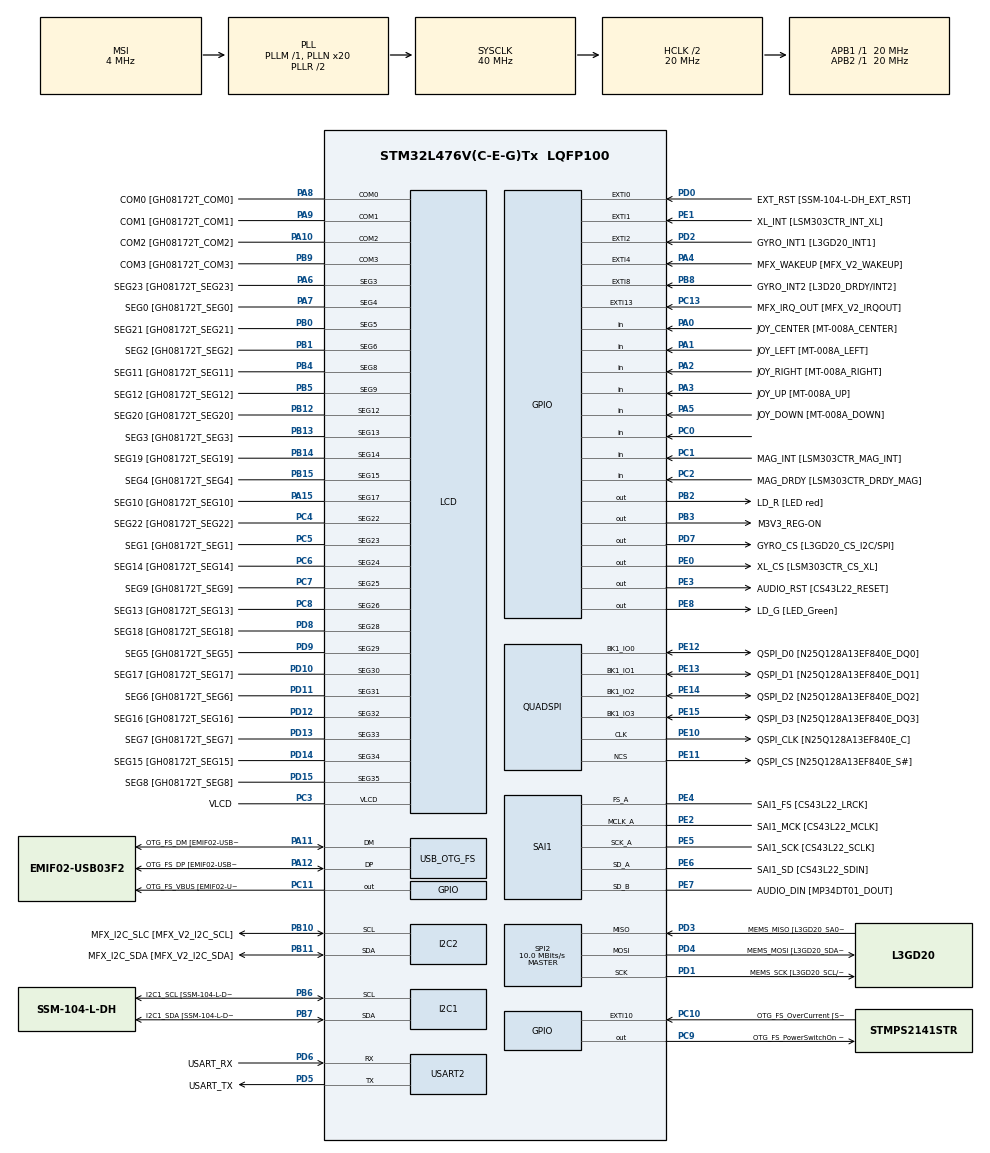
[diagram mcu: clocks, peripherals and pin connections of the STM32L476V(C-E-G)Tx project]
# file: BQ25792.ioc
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I2C1.Timing=0x00404C74
I2C2.Timing=0x00404C74
Mcu.Family=STM32L4
Mcu.Name=STM32L476V(C-E-G)Tx
Mcu.Package=LQFP100
NVIC.OTG_FS_IRQn=true\:0\:0\:false\:false\:true\:true\:true\:true
NVIC.PriorityGroup=NVIC_PRIORITYGROUP_4
NVIC.USART2_IRQn=true\:0\:0\:false\:false\:true\:true\:true\:true
PA0.GPIO_Label=JOY_CENTER [MT-008A_CENTER]
PA0.GPIO_Mode=GPIO_MODE_INPUT
PA0.GPIO_PuPd=GPIO_PULLDOWN
PA0.Signal=GPIO_Input
PA1.GPIO_Label=JOY_LEFT [MT-008A_LEFT]
PA1.GPIO_Mode=GPIO_MODE_INPUT
PA1.GPIO_PuPd=GPIO_PULLDOWN
PA1.Signal=GPIO_Input
PA10.GPIO_Label=COM2 [GH08172T_COM2]
PA10.GPIO_Mode=GPIO_MODE_AF_PP
PA10.GPIO_PuPd=GPIO_NOPULL
PA10.GPIO_Speed=GPIO_SPEED_FREQ_LOW
PA10.Mode=1/4 Duty Cycle
PA10.Signal=LCD_COM2
PA11.GPIO_Label=OTG_FS_DM [EMIF02-USB03F2_D-out]
PA11.GPIO_Mode=GPIO_MODE_AF_PP
PA11.GPIO_PuPd=GPIO_NOPULL
PA11.GPIO_Speed=GPIO_SPEED_FREQ_VERY_HIGH
PA11.Mode=Host_Only
PA11.Signal=USB_OTG_FS_DM
PA12.GPIO_Label=OTG_FS_DP [EMIF02-USB03F2_D+out]
PA12.GPIO_Mode=GPIO_MODE_AF_PP
PA12.GPIO_PuPd=GPIO_NOPULL
PA12.GPIO_Speed=GPIO_SPEED_FREQ_VERY_HIGH
PA12.Mode=Host_Only
PA12.Signal=USB_OTG_FS_DP
PA13\ (JTMS-SWDIO).GPIO_Label=SWDIO
PA13\ (JTMS-SWDIO).Mode=Serial_Wire
PA13\ (JTMS-SWDIO).Signal=SYS_JTMS-SWDIO
PA14\ (JTCK-SWCLK).GPIO_Label=SWCLK
PA14\ (JTCK-SWCLK).Mode=Serial_Wire
PA14\ (JTCK-SWCLK).Signal=SYS_JTCK-SWCLK
PA15\ (JTDI).GPIO_Label=SEG10 [GH08172T_SEG10]
PA15\ (JTDI).GPIO_Mode=GPIO_MODE_AF_PP
PA15\ (JTDI).GPIO_PuPd=GPIO_NOPULL
PA15\ (JTDI).GPIO_Speed=GPIO_SPEED_FREQ_LOW
PA15\ (JTDI).Mode=SEG17
PA15\ (JTDI).Signal=LCD_SEG17
PA2.GPIO_Label=JOY_RIGHT [MT-008A_RIGHT]
PA2.GPIO_Mode=GPIO_MODE_INPUT
PA2.GPIO_PuPd=GPIO_PULLDOWN
PA2.Signal=GPIO_Input
PA3.GPIO_Label=JOY_UP [MT-008A_UP]
PA3.GPIO_Mode=GPIO_MODE_INPUT
PA3.GPIO_PuPd=GPIO_PULLDOWN
PA3.Signal=GPIO_Input
PA4.GPIO_Label=MFX_WAKEUP [MFX_V2_WAKEUP]
PA4.GPIO_ModeDefaultEXTI=GPIO_MODE_EVT_RISING
PA4.GPIO_PuPd=GPIO_NOPULL
PA4.Signal=GPXTI4
PA5.GPIO_Label=JOY_DOWN [MT-008A_DOWN]
PA5.GPIO_Mode=GPIO_MODE_INPUT
PA5.GPIO_PuPd=GPIO_PULLDOWN
PA5.Signal=GPIO_Input
PA6.GPIO_Label=SEG23 [GH08172T_SEG23]
PA6.GPIO_Mode=GPIO_MODE_AF_PP
PA6.GPIO_PuPd=GPIO_NOPULL
PA6.GPIO_Speed=GPIO_SPEED_FREQ_LOW
PA6.Mode=SEG3
PA6.Signal=LCD_SEG3
PA7.GPIO_Label=SEG0 [GH08172T_SEG0]
PA7.GPIO_Mode=GPIO_MODE_AF_PP
PA7.GPIO_PuPd=GPIO_NOPULL
PA7.GPIO_Speed=GPIO_SPEED_FREQ_LOW
PA7.Mode=SEG4
PA7.Signal=LCD_SEG4
PA8.GPIO_Label=COM0 [GH08172T_COM0]
PA8.GPIO_Mode=GPIO_MODE_AF_PP
PA8.GPIO_PuPd=GPIO_NOPULL
PA8.GPIO_Speed=GPIO_SPEED_FREQ_LOW
PA8.Mode=1/4 Duty Cycle
PA8.Signal=LCD_COM0
PA9.GPIO_Label=COM1 [GH08172T_COM1]
PA9.GPIO_Mode=GPIO_MODE_AF_PP
PA9.GPIO_PuPd=GPIO_NOPULL
PA9.GPIO_Speed=GPIO_SPEED_FREQ_LOW
PA9.Mode=1/4 Duty Cycle
PA9.Signal=LCD_COM1
PB0.GPIO_Label=SEG21 [GH08172T_SEG21]
PB0.GPIO_Mode=GPIO_MODE_AF_PP
PB0.GPIO_PuPd=GPIO_NOPULL
PB0.GPIO_Speed=GPIO_SPEED_FREQ_LOW
PB0.Mode=SEG5
PB0.Signal=LCD_SEG5
PB1.GPIO_Label=SEG2 [GH08172T_SEG2]
PB1.GPIO_Mode=GPIO_MODE_AF_PP
PB1.GPIO_PuPd=GPIO_NOPULL
PB1.GPIO_Speed=GPIO_SPEED_FREQ_LOW
PB1.Mode=SEG6
PB1.Signal=LCD_SEG6
PB10.GPIO_Label=MFX_I2C_SLC [MFX_V2_I2C_SCL]
PB10.GPIO_Mode=GPIO_MODE_AF_OD
PB10.GPIO_Pu=GPIO_PULLUP
PB10.GPIO_Speed=GPIO_SPEED_FREQ_VERY_HIGH
PB10.Mode=I2C
PB10.Signal=I2C2_SCL
PB11.GPIO_Label=MFX_I2C_SDA [MFX_V2_I2C_SDA]
PB11.GPIO_Mode=GPIO_MODE_AF_OD
PB11.GPIO_Pu=GPIO_PULLUP
PB11.GPIO_Speed=GPIO_SPEED_FREQ_VERY_HIGH
PB11.Mode=I2C
PB11.Signal=I2C2_SDA
PB12.GPIO_Label=SEG20 [GH08172T_SEG20]
PB12.GPIO_Mode=GPIO_MODE_AF_PP
PB12.GPIO_PuPd=GPIO_NOPULL
PB12.GPIO_Speed=GPIO_SPEED_FREQ_LOW
PB12.Mode=SEG12
PB12.Signal=LCD_SEG12
PB13.GPIO_Label=SEG3 [GH08172T_SEG3]
PB13.GPIO_Mode=GPIO_MODE_AF_PP
PB13.GPIO_PuPd=GPIO_NOPULL
PB13.GPIO_Speed=GPIO_SPEED_FREQ_LOW
PB13.Mode=SEG13
PB13.Signal=LCD_SEG13
PB14.GPIO_Label=SEG19 [GH08172T_SEG19]
PB14.GPIO_Mode=GPIO_MODE_AF_PP
PB14.GPIO_PuPd=GPIO_NOPULL
PB14.GPIO_Speed=GPIO_SPEED_FREQ_LOW
PB14.Mode=SEG14
PB14.Signal=LCD_SEG14
PB15.GPIO_Label=SEG4 [GH08172T_SEG4]
PB15.GPIO_Mode=GPIO_MODE_AF_PP
PB15.GPIO_PuPd=GPIO_NOPULL
PB15.GPIO_Speed=GPIO_SPEED_FREQ_LOW
PB15.Mode=SEG15
PB15.Signal=LCD_SEG15
PB2.GPIO_Label=LD_R [LED red]
PB2.GPIO_ModeDefaultOutputPP=GPIO_MODE_OUTPUT_PP
PB2.GPIO_PuPd=GPIO_PULLUP
PB2.GPIO_Speed=GPIO_SPEED_FREQ_VERY_HIGH
PB2.Signal=GPIO_Output
PB3\ (JTDO-TRACESWO).GPIO_Label=M3V3_REG-ON
PB3\ (JTDO-TRACESWO).GPIO_ModeDefaultOutputPP=GPIO_MODE_OUTPUT_PP
PB3\ (JTDO-TRACESWO).GPIO_PuPd=GPIO_NOPULL
PB3\ (JTDO-TRACESWO).GPIO_Speed=GPIO_SPEED_FREQ_LOW
PB3\ (JTDO-TRACESWO).Signal=GPIO_Output
PB4\ (NJTRST).GPIO_Label=SEG11 [GH08172T_SEG11]
PB4\ (NJTRST).GPIO_Mode=GPIO_MODE_AF_PP
PB4\ (NJTRST).GPIO_PuPd=GPIO_NOPULL
PB4\ (NJTRST).GPIO_Speed=GPIO_SPEED_FREQ_LOW
PB4\ (NJTRST).Mode=SEG8
PB4\ (NJTRST).Signal=LCD_SEG8
PB5.GPIO_Label=SEG12 [GH08172T_SEG12]
PB5.GPIO_Mode=GPIO_MODE_AF_PP
PB5.GPIO_PuPd=GPIO_NOPULL
PB5.GPIO_Speed=GPIO_SPEED_FREQ_LOW
PB5.Mode=SEG9
PB5.Signal=LCD_SEG9
PB6.GPIO_FM6=__NULL
PB6.GPIO_Label=I2C1_SCL [SSM-104-L-DH_SCL]
PB6.GPIO_Mode=GPIO_MODE_AF_OD
PB6.GPIO_Pu=GPIO_PULLUP
PB6.GPIO_Speed=GPIO_SPEED_FREQ_VERY_HIGH
PB6.Mode=I2C
PB6.Signal=I2C1_SCL
PB7.GPIO_FM7=__NULL
PB7.GPIO_Label=I2C1_SDA [SSM-104-L-DH_SDA]
PB7.GPIO_Mode=GPIO_MODE_AF_OD
PB7.GPIO_Pu=GPIO_PULLUP
PB7.GPIO_Speed=GPIO_SPEED_FREQ_VERY_HIGH
PB7.Mode=I2C
PB7.Signal=I2C1_SDA
PB8.GPIO_Label=GYRO_INT2 [L3D20_DRDY/INT2]
PB8.GPIO_ModeDefaultEXTI=GPIO_MODE_EVT_RISING
PB8.GPIO_PuPd=GPIO_NOPULL
PB8.Signal=GPXTI8
PB9.GPIO_FM9=__NULL
PB9.GPIO_Label=COM3 [GH08172T_COM3]
PB9.GPIO_Mode=GPIO_MODE_AF_PP
PB9.GPIO_PuPd=GPIO_NOPULL
PB9.GPIO_Speed=GPIO_SPEED_FREQ_LOW
PB9.Mode=1/4 Duty Cycle
PB9.Signal=LCD_COM3
PC0.Signal=GPIO_Input
PC1.GPIO_Label=MAG_INT [LSM303CTR_MAG_INT]
PC1.GPIO_Mode=GPIO_MODE_INPUT
PC1.GPIO_PuPd=GPIO_NOPULL
PC1.Signal=GPIO_Input
PC10.GPIO_Label=OTG_FS_OverCurrent [STMPS2141STR_FAULT]
PC10.GPIO_ModeDefaultEXTI=GPIO_MODE_EVT_RISING
PC10.GPIO_PuPd=GPIO_NOPULL
PC10.Signal=GPXTI10
PC11.GPIO_Label=OTG_FS_VBUS [EMIF02-USB03F2_Vbus]
PC11.GPIO_ModeDefaultOutputPP=GPIO_MODE_OUTPUT_PP
PC11.GPIO_PuPd=GPIO_NOPULL
PC11.GPIO_Speed=GPIO_SPEED_FREQ_LOW
PC11.Signal=GPIO_Output
PC13.GPIO_Label=MFX_IRQ_OUT [MFX_V2_IRQOUT]
PC13.GPIO_ModeDefaultEXTI=GPIO_MODE_EVT_RISING
PC13.GPIO_PuPd=GPIO_NOPULL
PC13.Signal=GPXTI13
PC14-OSC32_IN\ (PC14).Mode=LSE-External-Oscillator
PC14-OSC32_IN\ (PC14).Signal=RCC_OSC32_IN
PC15-OSC32_OUT\ (PC15).Mode=LSE-External-Oscillator
PC15-OSC32_OUT\ (PC15).Signal=RCC_OSC32_OUT
PC2.GPIO_Label=MAG_DRDY [LSM303CTR_DRDY_MAG]
PC2.GPIO_Mode=GPIO_MODE_INPUT
PC2.GPIO_PuPd=GPIO_NOPULL
PC2.Signal=GPIO_Input
PC3.GPIO_Label=VLCD
PC3.GPIO_Mode=GPIO_MODE_AF_PP
PC3.GPIO_PuPd=GPIO_NOPULL
PC3.GPIO_Speed=GPIO_SPEED_FREQ_LOW
PC3.Mode=1/4 Duty Cycle
PC3.Signal=LCD_VLCD
PC4.GPIO_Label=SEG22 [GH08172T_SEG22]
PC4.GPIO_Mode=GPIO_MODE_AF_PP
PC4.GPIO_PuPd=GPIO_NOPULL
PC4.GPIO_Speed=GPIO_SPEED_FREQ_LOW
PC4.Mode=SEG22
PC4.Signal=LCD_SEG22
PC5.GPIO_Label=SEG1 [GH08172T_SEG1]
PC5.GPIO_Mode=GPIO_MODE_AF_PP
PC5.GPIO_PuPd=GPIO_NOPULL
PC5.GPIO_Speed=GPIO_SPEED_FREQ_LOW
PC5.Mode=SEG23
PC5.Signal=LCD_SEG23
PC6.GPIO_Label=SEG14 [GH08172T_SEG14]
PC6.GPIO_Mode=GPIO_MODE_AF_PP
PC6.GPIO_PuPd=GPIO_NOPULL
PC6.GPIO_Speed=GPIO_SPEED_FREQ_LOW
PC6.Mode=SEG24
PC6.Signal=LCD_SEG24
PC7.GPIO_Label=SEG9 [GH08172T_SEG9]
PC7.GPIO_Mode=GPIO_MODE_AF_PP
PC7.GPIO_PuPd=GPIO_NOPULL
PC7.GPIO_Speed=GPIO_SPEED_FREQ_LOW
PC7.Mode=SEG25
PC7.Signal=LCD_SEG25
PC8.GPIO_Label=SEG13 [GH08172T_SEG13]
PC8.GPIO_Mode=GPIO_MODE_AF_PP
PC8.GPIO_PuPd=GPIO_NOPULL
PC8.GPIO_Speed=GPIO_SPEED_FREQ_LOW
PC8.Mode=SEG26
PC8.Signal=LCD_SEG26
PC9.GPIO_Label=OTG_FS_PowerSwitchOn [STMPS2141STR_EN]
PC9.GPIO_ModeDefaultOutputPP=GPIO_MODE_OUTPUT_PP
PC9.GPIO_PuPd=GPIO_NOPULL
PC9.GPIO_Speed=GPIO_SPEED_FREQ_LOW
PC9.PinState=GPIO_PIN_SET
PC9.Signal=GPIO_Output
PD0.GPIO_Label=EXT_RST [SSM-104-L-DH_EXT_RST]
PD0.GPIO_ModeDefaultEXTI=GPIO_MODE_EVT_RISING
PD0.GPIO_PuPd=GPIO_NOPULL
PD0.Signal=GPXTI0
PD1.GPIO_Label=MEMS_SCK [L3GD20_SCL/SPC]
PD1.GPIO_Mode=GPIO_MODE_AF_PP
PD1.GPIO_PuPd=GPIO_NOPULL
PD1.GPIO_Speed=GPIO_SPEED_FREQ_VERY_HIGH
PD1.Mode=Full_Duplex_Master
PD1.Signal=SPI2_SCK
PD10.GPIO_Label=SEG17 [GH08172T_SEG17]
PD10.GPIO_Mode=GPIO_MODE_AF_PP
PD10.GPIO_PuPd=GPIO_NOPULL
PD10.GPIO_Speed=GPIO_SPEED_FREQ_LOW
PD10.Mode=SEG30
PD10.Signal=LCD_SEG30
PD11.GPIO_Label=SEG6 [GH08172T_SEG6]
PD11.GPIO_Mode=GPIO_MODE_AF_PP
PD11.GPIO_PuPd=GPIO_NOPULL
PD11.GPIO_Speed=GPIO_SPEED_FREQ_LOW
PD11.Mode=SEG31
PD11.Signal=LCD_SEG31
PD12.GPIO_Label=SEG16 [GH08172T_SEG16]
PD12.GPIO_Mode=GPIO_MODE_AF_PP
PD12.GPIO_PuPd=GPIO_NOPULL
PD12.GPIO_Speed=GPIO_SPEED_FREQ_LOW
PD12.Mode=SEG32
PD12.Signal=LCD_SEG32
PD13.GPIO_Label=SEG7 [GH08172T_SEG7]
PD13.GPIO_Mode=GPIO_MODE_AF_PP
PD13.GPIO_PuPd=GPIO_NOPULL
PD13.GPIO_Speed=GPIO_SPEED_FREQ_LOW
PD13.Mode=SEG33
PD13.Signal=LCD_SEG33
PD14.GPIO_Label=SEG15 [GH08172T_SEG15]
PD14.GPIO_Mode=GPIO_MODE_AF_PP
PD14.GPIO_PuPd=GPIO_NOPULL
PD14.GPIO_Speed=GPIO_SPEED_FREQ_LOW
PD14.Mode=SEG34
PD14.Signal=LCD_SEG34
PD15.GPIO_Label=SEG8 [GH08172T_SEG8]
PD15.GPIO_Mode=GPIO_MODE_AF_PP
PD15.GPIO_PuPd=GPIO_NOPULL
PD15.GPIO_Speed=GPIO_SPEED_FREQ_LOW
PD15.Mode=SEG35
PD15.Signal=LCD_SEG35
PD2.GPIO_Label=GYRO_INT1 [L3GD20_INT1]
PD2.GPIO_ModeDefaultEXTI=GPIO_MODE_EVT_RISING
PD2.GPIO_PuPd=GPIO_NOPULL
PD2.Signal=GPXTI2
PD3.GPIO_Label=MEMS_MISO [L3GD20_SA0/SDO]
PD3.GPIO_Mode=GPIO_MODE_AF_PP
PD3.GPIO_PuPd=GPIO_NOPULL
PD3.GPIO_Speed=GPIO_SPEED_FREQ_VERY_HIGH
PD3.Mode=Full_Duplex_Master
PD3.Signal=SPI2_MISO
PD4.GPIO_Label=MEMS_MOSI [L3GD20_SDA/SDI/SDO]
PD4.GPIO_Mode=GPIO_MODE_AF_PP
PD4.GPIO_PuPd=GPIO_NOPULL
PD4.GPIO_Speed=GPIO_SPEED_FREQ_VERY_HIGH
PD4.Mode=Full_Duplex_Master
PD4.Signal=SPI2_MOSI
PD5.GPIO_Label=USART_TX
PD5.GPIO_Mode=GPIO_MODE_AF_PP
PD5.GPIO_PuPd=GPIO_PULLUP
PD5.GPIO_Speed=GPIO_SPEED_FREQ_VERY_HIGH
PD5.Mode=Asynchronous
PD5.Signal=USART2_TX
PD6.GPIO_Label=USART_RX
PD6.GPIO_Mode=GPIO_MODE_AF_PP
PD6.GPIO_PuPd=GPIO_PULLUP
PD6.GPIO_Speed=GPIO_SPEED_FREQ_VERY_HIGH
PD6.Mode=Asynchronous
PD6.Signal=USART2_RX
PD7.GPIO_Label=GYRO_CS [L3GD20_CS_I2C/SPI]
PD7.GPIO_ModeDefaultOutputPP=GPIO_MODE_OUTPUT_PP
PD7.GPIO_PuPd=GPIO_NOPULL
PD7.GPIO_Speed=GPIO_SPEED_FREQ_VERY_HIGH
PD7.Signal=GPIO_Output
PD8.GPIO_Label=SEG18 [GH08172T_SEG18]
PD8.GPIO_Mode=GPIO_MODE_AF_PP
PD8.GPIO_PuPd=GPIO_NOPULL
PD8.GPIO_Speed=GPIO_SPEED_FREQ_LOW
PD8.Mode=SEG28
PD8.Signal=LCD_SEG28
PD9.GPIO_Label=SEG5 [GH08172T_SEG5]
PD9.GPIO_Mode=GPIO_MODE_AF_PP
PD9.GPIO_PuPd=GPIO_NOPULL
PD9.GPIO_Speed=GPIO_SPEED_FREQ_LOW
PD9.Mode=SEG29
PD9.Signal=LCD_SEG29
PE0.GPIO_Label=XL_CS [LSM303CTR_CS_XL]
PE0.GPIO_ModeDefaultOutputPP=GPIO_MODE_OUTPUT_PP
PE0.GPIO_PuPd=GPIO_NOPULL
PE0.GPIO_Speed=GPIO_SPEED_FREQ_LOW
PE0.Signal=GPIO_Output
PE1.GPIO_Label=XL_INT [LSM303CTR_INT_XL]
PE1.GPIO_ModeDefaultEXTI=GPIO_MODE_EVT_RISING
PE1.GPIO_PuPd=GPIO_NOPULL
PE1.Signal=GPXTI1
PE10.GPIO_Label=QSPI_CLK [N25Q128A13EF840E_C]
PE10.GPIO_Mode=GPIO_MODE_AF_PP
PE10.GPIO_PuPd=GPIO_NOPULL
PE10.GPIO_Speed=GPIO_SPEED_FREQ_VERY_HIGH
PE10.Mode=Single Bank
PE10.Signal=QUADSPI_CLK
PE11.GPIO_Label=QSPI_CS [N25Q128A13EF840E_S\#]
PE11.GPIO_Mode=GPIO_MODE_AF_PP
PE11.GPIO_PuPd=GPIO_NOPULL
PE11.GPIO_Speed=GPIO_SPEED_FREQ_VERY_HIGH
PE11.Mode=Single Bank
PE11.Signal=QUADSPI_NCS
PE12.GPIO_Label=QSPI_D0 [N25Q128A13EF840E_DQ0]
PE12.GPIO_Mode=GPIO_MODE_AF_PP
PE12.GPIO_PuPd=GPIO_NOPULL
PE12.GPIO_Speed=GPIO_SPEED_FREQ_VERY_HIGH
PE12.Mode=Single Bank
PE12.Signal=QUADSPI_BK1_IO0
PE13.GPIO_Label=QSPI_D1 [N25Q128A13EF840E_DQ1]
PE13.GPIO_Mode=GPIO_MODE_AF_PP
PE13.GPIO_PuPd=GPIO_NOPULL
PE13.GPIO_Speed=GPIO_SPEED_FREQ_VERY_HIGH
PE13.Mode=Single Bank
PE13.Signal=QUADSPI_BK1_IO1
PE14.GPIO_Label=QSPI_D2 [N25Q128A13EF840E_DQ2]
PE14.GPIO_Mode=GPIO_MODE_AF_PP
PE14.GPIO_PuPd=GPIO_NOPULL
PE14.GPIO_Speed=GPIO_SPEED_FREQ_VERY_HIGH
PE14.Mode=Single Bank
PE14.Signal=QUADSPI_BK1_IO2
PE15.GPIO_Label=QSPI_D3 [N25Q128A13EF840E_DQ3]
PE15.GPIO_Mode=GPIO_MODE_AF_PP
PE15.GPIO_PuPd=GPIO_NOPULL
PE15.GPIO_Speed=GPIO_SPEED_FREQ_VERY_HIGH
PE15.Mode=Single Bank
PE15.Signal=QUADSPI_BK1_IO3
PE2.GPIO_Label=SAI1_MCK [CS43L22_MCLK]
PE2.GPIO_Mode=GPIO_MODE_AF_PP
PE2.GPIO_PuPd=GPIO_NOPULL
PE2.GPIO_Speed=GPIO_SPEED_FREQ_VERY_HIGH
PE2.Mode=SAI_A_MasterWithClock
PE2.Signal=SAI1_MCLK_A
PE3.GPIO_Label=AUDIO_RST [CS43L22_RESET]
PE3.GPIO_ModeDefaultOutputPP=GPIO_MODE_OUTPUT_PP
PE3.GPIO_PuPd=GPIO_NOPULL
PE3.GPIO_Speed=GPIO_SPEED_FREQ_HIGH
PE3.Signal=GPIO_Output
PE4.GPIO_Label=SAI1_FS [CS43L22_LRCK]
PE4.GPIO_Mode=GPIO_MODE_AF_PP
PE4.GPIO_PuPd=GPIO_NOPULL
PE4.GPIO_Speed=GPIO_SPEED_FREQ_VERY_HIGH
PE4.Mode=SAI_A_MasterWithClock
PE4.Signal=SAI1_FS_A
PE5.GPIO_Label=SAI1_SCK [CS43L22_SCLK]
PE5.GPIO_Mode=GPIO_MODE_AF_PP
PE5.GPIO_PuPd=GPIO_NOPULL
PE5.GPIO_Speed=GPIO_SPEED_FREQ_VERY_HIGH
PE5.Mode=SAI_A_MasterWithClock
PE5.Signal=SAI1_SCK_A
PE6.GPIO_Label=SAI1_SD [CS43L22_SDIN]
PE6.GPIO_Mode=GPIO_MODE_AF_PP
PE6.GPIO_PuPd=GPIO_NOPULL
PE6.GPIO_Speed=GPIO_SPEED_FREQ_VERY_HIGH
PE6.Mode=SAI_A_MasterWithClock
PE6.Signal=SAI1_SD_A
PE7.GPIO_Label=AUDIO_DIN [MP34DT01_DOUT]
PE7.GPIO_Mode=GPIO_MODE_AF_PP
PE7.GPIO_PuPd=GPIO_NOPULL
PE7.GPIO_Speed=GPIO_SPEED_FREQ_VERY_HIGH
PE7.Mode=SAI_B_SyncSlave
PE7.Signal=SAI1_SD_B
PE8.GPIO_Label=LD_G [LED_Green]
PE8.GPIO_ModeDefaultOutputPP=GPIO_MODE_OUTPUT_PP
PE8.GPIO_PuPd=GPIO_PULLUP
PE8.GPIO_Speed=GPIO_SPEED_FREQ_VERY_HIGH
PE8.Signal=GPIO_Output
PE9.GPIO_Label=AUDIO_CLK [MP34DT01_CLK]
PE9.GPIO_Mode=GPIO_MODE_AF_PP
PE9.GPIO_PuPd=GPIO_NOPULL
PE9.GPIO_Speed=GPIO_SPEED_FREQ_LOW
PE9.Signal=SAI1_FS_B
PH0-OSC_IN\ (PH0).Mode=HSE-External-Oscillator
PH0-OSC_IN\ (PH0).Signal=RCC_OSC_IN
PH1-OSC_OUT\ (PH1).Mode=HSE-External-Oscillator
PH1-OSC_OUT\ (PH1).Signal=RCC_OSC_OUT
ProjectManager.HeapSize=0x200
ProjectManager.StackSize=0x400
ProjectManager.TargetToolchain=STM32CubeIDE
QUADSPI.ClockPrescaler=1
QUADSPI.FifoThreshold=4
QUADSPI.FlashSize=24
QUADSPI.SampleShifting=QSPI_SAMPLE_SHIFTING_HALFCYCLE
RCC.ADCFreq_Value=48000000
RCC.AHBCLKDivider=RCC_SYSCLK_DIV2
RCC.AHBFreq_Value=20000000
RCC.APB1Freq_Value=20000000
RCC.APB1TimFreq_Value=20000000
RCC.APB2Freq_Value=20000000
RCC.APB2TimFreq_Value=20000000
RCC.CortexFreq_Value=20000000
RCC.HCLKFreq_Value=20000000
RCC.HSE_VALUE=8000000
RCC.HSI_VALUE=16000000
RCC.MSI_VALUE=4000000
RCC.PLLN=20
RCC.PLLSAI1N=24
RCC.PREFETCH_ENABLE=1
RCC.SYSCLKFreq_VALUE=40000000
RCC.SYSCLKSource=RCC_SYSCLKSOURCE_PLLCLK
RCC.USBFreq_Value=48000000
RCC.VCOOutputFreq_Value=80000000
SAI1.Instance-SAI_A_MasterWithClock=SAI$Index_Block_A
SAI1.Instance-SAI_B_SyncSlave=SAI$Index_Block_B
SAI1.MClockEnable-SAI_A_MasterWithClock=SAI_MASTERCLOCK_ENABLE
SAI1.Synchro-SAI_B_SyncSlave=SAI_SYNCHRONOUS
SAI1.VirtualMode-SAI_A_MasterWithClock=VM_MASTER
SAI1.VirtualMode-SAI_B_SyncSlave=VM_SLAVE
SPI2.CalculateBaudRate=10.0 MBits/s
SPI2.Direction=SPI_DIRECTION_2LINES
SPI2.Mode=SPI_MODE_MASTER
SPI2.VirtualType=VM_MASTER
USART2.VirtualMode-Asynchronous=VM_ASYNC
USB_HOST.BSP.number=1
USB_HOST.USBH_HandleTypeDef=hUsbHostFS
USB_HOST.VirtualModeFS=Cdc
USB_HOST0.BSP.STBoard=false
USB_HOST0.BSP.api=Unknown
USB_HOST0.BSP.instance=PC9
USB_HOST0.BSP.ip=GPIO
USB_HOST0.BSP.mode=Output
USB_HOST0.BSP.name=Drive_VBUS_FS
USB_HOST0.BSP.solution=PC9
USB_OTG_FS.VirtualMode=Host_Only
USB_OTG_FS.phy_itface=HCD_PHY_EMBEDDED
VP_USB_HOST_VS_USB_HOST_CDC_FS.Mode=CDC_FS
board=STM32L476G-DISCO

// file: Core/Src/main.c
/* USER CODE BEGIN Header */
/**
  ******************************************************************************
  * @file           : main.c
  * @brief          : Main program body
  ******************************************************************************
  * @attention
  *
  * Copyright (c) 2023 STMicroelectronics.
  * All rights reserved.
  *
  * This software is licensed under terms that can be found in the LICENSE file
  * in the root directory of this software component.
  * If no LICENSE file comes with this software, it is provided AS-IS.
  *
  ******************************************************************************
  */
/* USER CODE END Header */
#include "main.h"
#include "usb_host.h"

/* USER CODE BEGIN Includes */
#include "stdlib.h"
#include "BQ25792.h"
#include "ncurses.h"
/* USER CODE END Includes */

/* USER CODE BEGIN PD */

#define I2C_EEPROM_ADDRESS 0xA0
#define I2C_BQ25792_ADDRESS (0x6B<<1)
/* USER CODE END PD */

I2C_HandleTypeDef hi2c1;
I2C_HandleTypeDef hi2c2;

LCD_HandleTypeDef hlcd;

QSPI_HandleTypeDef hqspi;

SAI_HandleTypeDef hsai_BlockA1;
SAI_HandleTypeDef hsai_BlockB1;

SPI_HandleTypeDef hspi2;

UART_HandleTypeDef huart2;

void SystemClock_Config(void);
void PeriphCommonClock_Config(void);
static void MX_GPIO_Init(void);
static void MX_I2C1_Init(void);
static void MX_I2C2_Init(void);
static void MX_LCD_Init(void);
static void MX_QUADSPI_Init(void);
static void MX_SAI1_Init(void);
static void MX_SPI2_Init(void);
static void MX_USART2_UART_Init(void);
void MX_USB_HOST_Process(void);

int main(void)
{
  /* USER CODE BEGIN 1 */

	char bufforTx[128];
	int len;
  /* USER CODE END 1 */

  /* MCU Configuration--------------------------------------------------------*/

  /* Reset of all peripherals, Initializes the Flash interface and the Systick. */
  HAL_Init();

  /* Configure the system clock */
  SystemClock_Config();

/* Configure the peripherals common clocks */
  PeriphCommonClock_Config();

  /* Initialize all configured peripherals */
  MX_GPIO_Init();
  MX_I2C1_Init();
  MX_I2C2_Init();
  MX_LCD_Init();
  MX_QUADSPI_Init();
  MX_SAI1_Init();
  MX_SPI2_Init();
  MX_USART2_UART_Init();
  MX_USB_HOST_Init();
  /* USER CODE BEGIN 2 */

  //when compiled
	HAL_UART_Transmit(&huart2, "\f", 1, 10);
	len = sprintf(bufforTx,"%sCompiled @ %s %s\r\n", NCURSES_RESET, __DATE__, __TIME__);
	HAL_UART_Transmit(&huart2, bufforTx, len, 10);

  if(BQ25792_Init() != HAL_OK)
  {
  	  HAL_UART_Transmit(&huart2, "BQ25792_Init: Hal error\r\n", 25, 10);
  	  while(1);
  }
  /* USER CODE END 2 */

  /* Infinite loop */
  while (1)
  {
    MX_USB_HOST_Process();

    /* USER CODE BEGIN 3 */

    BQ25792_Debug();

    HAL_Delay(500);
    HAL_GPIO_TogglePin(LD_G_GPIO_Port, LD_G_Pin);

    if(HAL_GPIO_ReadPin(JOY_CENTER_GPIO_Port, JOY_CENTER_Pin))
    {
		char pData[1];
		if(BQ25792_Read(BQ25792_CHARGER_CONTROL_0, pData, 1) == HAL_OK)
		{
			pData[0] ^= BQ25792_CHARGER_CONTROL_0_EN_CHG;
			BQ25792_Write(BQ25792_CHARGER_CONTROL_0, pData, 1);
		}
    }

    if(HAL_GPIO_ReadPin(JOY_UP_GPIO_Port, JOY_UP_Pin))
	{
		char pData[2];
		if(BQ25792_Read(BQ25792_CHARGE_CURRENT_LIMIT, pData, 2) == HAL_OK)
		{
			int current = pData[0] << 8 | pData[1];
			if(current < 500)
				current++;
			if(current > 500)
				current = 500;
			pData[0] = (current << 8) & 0xff;
			pData[1] = current & 0xff;
			BQ25792_Write(BQ25792_CHARGE_CURRENT_LIMIT, pData, 2);
		}
	}
    else if(HAL_GPIO_ReadPin(JOY_DOWN_GPIO_Port, JOY_DOWN_Pin))
	{
		char pData[2];
		if(BQ25792_Read(BQ25792_CHARGE_CURRENT_LIMIT, pData, 2) == HAL_OK)
		{
			int current = pData[0] << 8 | pData[1];
			if(current > 5)
				current--;
			if(current < 5)
				current = 5;
			pData[0] = (current << 8) & 0xff;
			pData[1] = current & 0xff;
			BQ25792_Write(BQ25792_CHARGE_CURRENT_LIMIT, pData, 2);
		}
	}

    if(HAL_GPIO_ReadPin(JOY_LEFT_GPIO_Port, JOY_LEFT_Pin))
    {
		char pData[1];
		if(BQ25792_Read(BQ25792_CHARGER_CONTROL_3, pData, 1) == HAL_OK)
		{
			pData[0] ^= BQ25792_CHARGER_CONTROL_3_EN_OTG;
			BQ25792_Write(BQ25792_CHARGER_CONTROL_3, pData, 1);
		}
    }

    if(BQ25792_WD_Feed() != HAL_OK)
    {
    	while(1)
        {
    		HAL_Delay(100);
            HAL_GPIO_TogglePin(LD_R_GPIO_Port, LD_R_Pin);
        }
    }
  }
  /* USER CODE END 3 */
}

void SystemClock_Config(void)
{
  RCC_OscInitTypeDef RCC_OscInitStruct = {0};
  RCC_ClkInitTypeDef RCC_ClkInitStruct = {0};

  /** Configure the main internal regulator output voltage
  */
  if (HAL_PWREx_ControlVoltageScaling(PWR_REGULATOR_VOLTAGE_SCALE1) != HAL_OK)
  {
    Error_Handler();
  }

  /** Configure LSE Drive Capability
  */
  HAL_PWR_EnableBkUpAccess();
  __HAL_RCC_LSEDRIVE_CONFIG(RCC_LSEDRIVE_LOW);

  /** Initializes the RCC Oscillators according to the specified parameters
  * in the RCC_OscInitTypeDef structure.
  */
  RCC_OscInitStruct.OscillatorType = RCC_OSCILLATORTYPE_LSI|RCC_OSCILLATORTYPE_LSE
                              |RCC_OSCILLATORTYPE_MSI;
  RCC_OscInitStruct.LSEState = RCC_LSE_ON;
  RCC_OscInitStruct.LSIState = RCC_LSI_ON;
  RCC_OscInitStruct.MSIState = RCC_MSI_ON;
  RCC_OscInitStruct.MSICalibrationValue = 0;
  RCC_OscInitStruct.MSIClockRange = RCC_MSIRANGE_6;
  RCC_OscInitStruct.PLL.PLLState = RCC_PLL_ON;
  RCC_OscInitStruct.PLL.PLLSource = RCC_PLLSOURCE_MSI;
  RCC_OscInitStruct.PLL.PLLM = 1;
  RCC_OscInitStruct.PLL.PLLN = 20;
  RCC_OscInitStruct.PLL.PLLP = RCC_PLLP_DIV7;
  RCC_OscInitStruct.PLL.PLLQ = RCC_PLLQ_DIV2;
  RCC_OscInitStruct.PLL.PLLR = RCC_PLLR_DIV2;
  if (HAL_RCC_OscConfig(&RCC_OscInitStruct) != HAL_OK)
  {
    Error_Handler();
  }

  /** Initializes the CPU, AHB and APB buses clocks
  */
  RCC_ClkInitStruct.ClockType = RCC_CLOCKTYPE_HCLK|RCC_CLOCKTYPE_SYSCLK
                              |RCC_CLOCKTYPE_PCLK1|RCC_CLOCKTYPE_PCLK2;
  RCC_ClkInitStruct.SYSCLKSource = RCC_SYSCLKSOURCE_PLLCLK;
  RCC_ClkInitStruct.AHBCLKDivider = RCC_SYSCLK_DIV2;
  RCC_ClkInitStruct.APB1CLKDivider = RCC_HCLK_DIV1;
  RCC_ClkInitStruct.APB2CLKDivider = RCC_HCLK_DIV1;

  if (HAL_RCC_ClockConfig(&RCC_ClkInitStruct, FLASH_LATENCY_1) != HAL_OK)
  {
    Error_Handler();
  }

  /** Enable MSI Auto calibration
  */
  HAL_RCCEx_EnableMSIPLLMode();
}

void PeriphCommonClock_Config(void)
{
  RCC_PeriphCLKInitTypeDef PeriphClkInit = {0};

  /** Initializes the peripherals clock
  */
  PeriphClkInit.PeriphClockSelection = RCC_PERIPHCLK_SAI1|RCC_PERIPHCLK_USB;
  PeriphClkInit.Sai1ClockSelection = RCC_SAI1CLKSOURCE_PLLSAI1;
  PeriphClkInit.UsbClockSelection = RCC_USBCLKSOURCE_PLLSAI1;
  PeriphClkInit.PLLSAI1.PLLSAI1Source = RCC_PLLSOURCE_MSI;
  PeriphClkInit.PLLSAI1.PLLSAI1M = 1;
  PeriphClkInit.PLLSAI1.PLLSAI1N = 24;
  PeriphClkInit.PLLSAI1.PLLSAI1P = RCC_PLLP_DIV7;
  PeriphClkInit.PLLSAI1.PLLSAI1Q = RCC_PLLQ_DIV2;
  PeriphClkInit.PLLSAI1.PLLSAI1R = RCC_PLLR_DIV2;
  PeriphClkInit.PLLSAI1.PLLSAI1ClockOut = RCC_PLLSAI1_SAI1CLK|RCC_PLLSAI1_48M2CLK;
  if (HAL_RCCEx_PeriphCLKConfig(&PeriphClkInit) != HAL_OK)
  {
    Error_Handler();
  }
}

static void MX_I2C1_Init(void)
{

  hi2c1.Instance = I2C1;
  hi2c1.Init.Timing = 0x00404C74;
  hi2c1.Init.OwnAddress1 = 0;
  hi2c1.Init.AddressingMode = I2C_ADDRESSINGMODE_7BIT;
  hi2c1.Init.DualAddressMode = I2C_DUALADDRESS_DISABLE;
  hi2c1.Init.OwnAddress2 = 0;
  hi2c1.Init.OwnAddress2Masks = I2C_OA2_NOMASK;
  hi2c1.Init.GeneralCallMode = I2C_GENERALCALL_DISABLE;
  hi2c1.Init.NoStretchMode = I2C_NOSTRETCH_DISABLE;
  if (HAL_I2C_Init(&hi2c1) != HAL_OK)
  {
    Error_Handler();
  }

  /** Configure Analogue filter
  */
  if (HAL_I2CEx_ConfigAnalogFilter(&hi2c1, I2C_ANALOGFILTER_ENABLE) != HAL_OK)
  {
    Error_Handler();
  }

  /** Configure Digital filter
  */
  if (HAL_I2CEx_ConfigDigitalFilter(&hi2c1, 0) != HAL_OK)
  {
    Error_Handler();
  }

}

static void MX_I2C2_Init(void)
{

  hi2c2.Instance = I2C2;
  hi2c2.Init.Timing = 0x00404C74;
  hi2c2.Init.OwnAddress1 = 0;
  hi2c2.Init.AddressingMode = I2C_ADDRESSINGMODE_7BIT;
  hi2c2.Init.DualAddressMode = I2C_DUALADDRESS_DISABLE;
  hi2c2.Init.OwnAddress2 = 0;
  hi2c2.Init.OwnAddress2Masks = I2C_OA2_NOMASK;
  hi2c2.Init.GeneralCallMode = I2C_GENERALCALL_DISABLE;
  hi2c2.Init.NoStretchMode = I2C_NOSTRETCH_DISABLE;
  if (HAL_I2C_Init(&hi2c2) != HAL_OK)
  {
    Error_Handler();
  }

  /** Configure Analogue filter
  */
  if (HAL_I2CEx_ConfigAnalogFilter(&hi2c2, I2C_ANALOGFILTER_ENABLE) != HAL_OK)
  {
    Error_Handler();
  }

  /** Configure Digital filter
  */
  if (HAL_I2CEx_ConfigDigitalFilter(&hi2c2, 0) != HAL_OK)
  {
    Error_Handler();
  }

}

static void MX_LCD_Init(void)
{

  hlcd.Instance = LCD;
  hlcd.Init.Prescaler = LCD_PRESCALER_1;
  hlcd.Init.Divider = LCD_DIVIDER_16;
  hlcd.Init.Duty = LCD_DUTY_1_4;
  hlcd.Init.Bias = LCD_BIAS_1_4;
  hlcd.Init.VoltageSource = LCD_VOLTAGESOURCE_INTERNAL;
  hlcd.Init.Contrast = LCD_CONTRASTLEVEL_0;
  hlcd.Init.DeadTime = LCD_DEADTIME_0;
  hlcd.Init.PulseOnDuration = LCD_PULSEONDURATION_0;
  hlcd.Init.MuxSegment = LCD_MUXSEGMENT_DISABLE;
  hlcd.Init.BlinkMode = LCD_BLINKMODE_OFF;
  hlcd.Init.BlinkFrequency = LCD_BLINKFREQUENCY_DIV8;
  hlcd.Init.HighDrive = LCD_HIGHDRIVE_DISABLE;
  if (HAL_LCD_Init(&hlcd) != HAL_OK)
  {
    Error_Handler();
  }

}

static void MX_QUADSPI_Init(void)
{

  /* QUADSPI parameter configuration*/
  hqspi.Instance = QUADSPI;
  hqspi.Init.ClockPrescaler = 1;
  hqspi.Init.FifoThreshold = 4;
  hqspi.Init.SampleShifting = QSPI_SAMPLE_SHIFTING_HALFCYCLE;
  hqspi.Init.FlashSize = 24;
  hqspi.Init.ChipSelectHighTime = QSPI_CS_HIGH_TIME_1_CYCLE;
  hqspi.Init.ClockMode = QSPI_CLOCK_MODE_0;
  if (HAL_QSPI_Init(&hqspi) != HAL_OK)
  {
    Error_Handler();
  }

}

static void MX_SAI1_Init(void)
{

  hsai_BlockA1.Instance = SAI1_Block_A;
  hsai_BlockA1.Init.Protocol = SAI_FREE_PROTOCOL;
  hsai_BlockA1.Init.AudioMode = SAI_MODEMASTER_TX;
  hsai_BlockA1.Init.DataSize = SAI_DATASIZE_8;
  hsai_BlockA1.Init.FirstBit = SAI_FIRSTBIT_MSB;
  hsai_BlockA1.Init.ClockStrobing = SAI_CLOCKSTROBING_FALLINGEDGE;
  hsai_BlockA1.Init.Synchro = SAI_ASYNCHRONOUS;
  hsai_BlockA1.Init.OutputDrive = SAI_OUTPUTDRIVE_DISABLE;
  hsai_BlockA1.Init.NoDivider = SAI_MASTERDIVIDER_ENABLE;
  hsai_BlockA1.Init.FIFOThreshold = SAI_FIFOTHRESHOLD_EMPTY;
  hsai_BlockA1.Init.AudioFrequency = SAI_AUDIO_FREQUENCY_192K;
  hsai_BlockA1.Init.SynchroExt = SAI_SYNCEXT_DISABLE;
  hsai_BlockA1.Init.MonoStereoMode = SAI_STEREOMODE;
  hsai_BlockA1.Init.CompandingMode = SAI_NOCOMPANDING;
  hsai_BlockA1.Init.TriState = SAI_OUTPUT_NOTRELEASED;
  hsai_BlockA1.FrameInit.FrameLength = 8;
  hsai_BlockA1.FrameInit.ActiveFrameLength = 1;
  hsai_BlockA1.FrameInit.FSDefinition = SAI_FS_STARTFRAME;
  hsai_BlockA1.FrameInit.FSPolarity = SAI_FS_ACTIVE_LOW;
  hsai_BlockA1.FrameInit.FSOffset = SAI_FS_FIRSTBIT;
  hsai_BlockA1.SlotInit.FirstBitOffset = 0;
  hsai_BlockA1.SlotInit.SlotSize = SAI_SLOTSIZE_DATASIZE;
  hsai_BlockA1.SlotInit.SlotNumber = 1;
  hsai_BlockA1.SlotInit.SlotActive = 0x00000000;
  if (HAL_SAI_Init(&hsai_BlockA1) != HAL_OK)
  {
    Error_Handler();
  }
  hsai_BlockB1.Instance = SAI1_Block_B;
  hsai_BlockB1.Init.Protocol = SAI_FREE_PROTOCOL;
  hsai_BlockB1.Init.AudioMode = SAI_MODESLAVE_RX;
  hsai_BlockB1.Init.DataSize = SAI_DATASIZE_8;
  hsai_BlockB1.Init.FirstBit = SAI_FIRSTBIT_MSB;
  hsai_BlockB1.Init.ClockStrobing = SAI_CLOCKSTROBING_FALLINGEDGE;
  hsai_BlockB1.Init.Synchro = SAI_SYNCHRONOUS;
  hsai_BlockB1.Init.OutputDrive = SAI_OUTPUTDRIVE_DISABLE;
  hsai_BlockB1.Init.FIFOThreshold = SAI_FIFOTHRESHOLD_EMPTY;
  hsai_BlockB1.Init.SynchroExt = SAI_SYNCEXT_DISABLE;
  hsai_BlockB1.Init.MonoStereoMode = SAI_STEREOMODE;
  hsai_BlockB1.Init.CompandingMode = SAI_NOCOMPANDING;
  hsai_BlockB1.Init.TriState = SAI_OUTPUT_NOTRELEASED;
  hsai_BlockB1.FrameInit.FrameLength = 8;
  hsai_BlockB1.FrameInit.ActiveFrameLength = 1;
  hsai_BlockB1.FrameInit.FSDefinition = SAI_FS_STARTFRAME;
  hsai_BlockB1.FrameInit.FSPolarity = SAI_FS_ACTIVE_LOW;
  hsai_BlockB1.FrameInit.FSOffset = SAI_FS_FIRSTBIT;
  hsai_BlockB1.SlotInit.FirstBitOffset = 0;
  hsai_BlockB1.SlotInit.SlotSize = SAI_SLOTSIZE_DATASIZE;
  hsai_BlockB1.SlotInit.SlotNumber = 1;
  hsai_BlockB1.SlotInit.SlotActive = 0x00000000;
  if (HAL_SAI_Init(&hsai_BlockB1) != HAL_OK)
  {
    Error_Handler();
  }

}

static void MX_SPI2_Init(void)
{

  /* SPI2 parameter configuration*/
  hspi2.Instance = SPI2;
  hspi2.Init.Mode = SPI_MODE_MASTER;
  hspi2.Init.Direction = SPI_DIRECTION_2LINES;
  hspi2.Init.DataSize = SPI_DATASIZE_4BIT;
  hspi2.Init.CLKPolarity = SPI_POLARITY_LOW;
  hspi2.Init.CLKPhase = SPI_PHASE_1EDGE;
  hspi2.Init.NSS = SPI_NSS_SOFT;
  hspi2.Init.BaudRatePrescaler = SPI_BAUDRATEPRESCALER_2;
  hspi2.Init.FirstBit = SPI_FIRSTBIT_MSB;
  hspi2.Init.TIMode = SPI_TIMODE_DISABLE;
  hspi2.Init.CRCCalculation = SPI_CRCCALCULATION_DISABLE;
  hspi2.Init.CRCPolynomial = 7;
  hspi2.Init.CRCLength = SPI_CRC_LENGTH_DATASIZE;
  hspi2.Init.NSSPMode = SPI_NSS_PULSE_ENABLE;
  if (HAL_SPI_Init(&hspi2) != HAL_OK)
  {
    Error_Handler();
  }

}

static void MX_USART2_UART_Init(void)
{

  huart2.Instance = USART2;
  huart2.Init.BaudRate = 115200;
  huart2.Init.WordLength = UART_WORDLENGTH_8B;
  huart2.Init.StopBits = UART_STOPBITS_1;
  huart2.Init.Parity = UART_PARITY_NONE;
  huart2.Init.Mode = UART_MODE_TX_RX;
  huart2.Init.HwFlowCtl = UART_HWCONTROL_NONE;
  huart2.Init.OverSampling = UART_OVERSAMPLING_16;
  huart2.Init.OneBitSampling = UART_ONE_BIT_SAMPLE_DISABLE;
  huart2.AdvancedInit.AdvFeatureInit = UART_ADVFEATURE_NO_INIT;
  if (HAL_UART_Init(&huart2) != HAL_OK)
  {
    Error_Handler();
  }

}

static void MX_GPIO_Init(void)
{
  GPIO_InitTypeDef GPIO_InitStruct = {0};

  /* GPIO Ports Clock Enable */
  __HAL_RCC_GPIOE_CLK_ENABLE();
  __HAL_RCC_GPIOC_CLK_ENABLE();
  __HAL_RCC_GPIOH_CLK_ENABLE();
  __HAL_RCC_GPIOA_CLK_ENABLE();
  __HAL_RCC_GPIOB_CLK_ENABLE();
  __HAL_RCC_GPIOD_CLK_ENABLE();

  /*Configure GPIO pin Output Level */
  HAL_GPIO_WritePin(GPIOE, AUDIO_RST_Pin|LD_G_Pin|XL_CS_Pin, GPIO_PIN_RESET);

  /*Configure GPIO pin Output Level */
  HAL_GPIO_WritePin(GPIOB, LD_R_Pin|M3V3_REG_ON_Pin, GPIO_PIN_RESET);

  /*Configure GPIO pin Output Level */
  HAL_GPIO_WritePin(OTG_FS_PowerSwitchOn_GPIO_Port, OTG_FS_PowerSwitchOn_Pin, GPIO_PIN_SET);

  /*Configure GPIO pin Output Level */
  HAL_GPIO_WritePin(OTG_FS_VBUS_GPIO_Port, OTG_FS_VBUS_Pin, GPIO_PIN_RESET);

  /*Configure GPIO pin Output Level */
  HAL_GPIO_WritePin(GYRO_CS_GPIO_Port, GYRO_CS_Pin, GPIO_PIN_RESET);

  /*Configure GPIO pin : AUDIO_RST_Pin */
  GPIO_InitStruct.Pin = AUDIO_RST_Pin;
  GPIO_InitStruct.Mode = GPIO_MODE_OUTPUT_PP;
  GPIO_InitStruct.Pull = GPIO_NOPULL;
  GPIO_InitStruct.Speed = GPIO_SPEED_FREQ_HIGH;
  HAL_GPIO_Init(AUDIO_RST_GPIO_Port, &GPIO_InitStruct);

  /*Configure GPIO pins : MFX_IRQ_OUT_Pin OTG_FS_OverCurrent_Pin */
  GPIO_InitStruct.Pin = MFX_IRQ_OUT_Pin|OTG_FS_OverCurrent_Pin;
  GPIO_InitStruct.Mode = GPIO_MODE_EVT_RISING;
  GPIO_InitStruct.Pull = GPIO_NOPULL;
  HAL_GPIO_Init(GPIOC, &GPIO_InitStruct);

  /*Configure GPIO pins : PC0 MAG_INT_Pin MAG_DRDY_Pin */
  GPIO_InitStruct.Pin = GPIO_PIN_0|MAG_INT_Pin|MAG_DRDY_Pin;
  GPIO_InitStruct.Mode = GPIO_MODE_INPUT;
  GPIO_InitStruct.Pull = GPIO_NOPULL;
  HAL_GPIO_Init(GPIOC, &GPIO_InitStruct);

  /*Configure GPIO pins : JOY_CENTER_Pin JOY_LEFT_Pin JOY_RIGHT_Pin JOY_UP_Pin
                           JOY_DOWN_Pin */
  GPIO_InitStruct.Pin = JOY_CENTER_Pin|JOY_LEFT_Pin|JOY_RIGHT_Pin|JOY_UP_Pin
                          |JOY_DOWN_Pin;
  GPIO_InitStruct.Mode = GPIO_MODE_INPUT;
  GPIO_InitStruct.Pull = GPIO_PULLDOWN;
  HAL_GPIO_Init(GPIOA, &GPIO_InitStruct);

  /*Configure GPIO pin : MFX_WAKEUP_Pin */
  GPIO_InitStruct.Pin = MFX_WAKEUP_Pin;
  GPIO_InitStruct.Mode = GPIO_MODE_EVT_RISING;
  GPIO_InitStruct.Pull = GPIO_NOPULL;
  HAL_GPIO_Init(MFX_WAKEUP_GPIO_Port, &GPIO_InitStruct);

  /*Configure GPIO pin : LD_R_Pin */
  GPIO_InitStruct.Pin = LD_R_Pin;
  GPIO_InitStruct.Mode = GPIO_MODE_OUTPUT_PP;
  GPIO_InitStruct.Pull = GPIO_PULLUP;
  GPIO_InitStruct.Speed = GPIO_SPEED_FREQ_VERY_HIGH;
  HAL_GPIO_Init(LD_R_GPIO_Port, &GPIO_InitStruct);

  /*Configure GPIO pin : LD_G_Pin */
  GPIO_InitStruct.Pin = LD_G_Pin;
  GPIO_InitStruct.Mode = GPIO_MODE_OUTPUT_PP;
  GPIO_InitStruct.Pull = GPIO_PULLUP;
  GPIO_InitStruct.Speed = GPIO_SPEED_FREQ_VERY_HIGH;
  HAL_GPIO_Init(LD_G_GPIO_Port, &GPIO_InitStruct);

  /*Configure GPIO pins : OTG_FS_PowerSwitchOn_Pin OTG_FS_VBUS_Pin */
  GPIO_InitStruct.Pin = OTG_FS_PowerSwitchOn_Pin|OTG_FS_VBUS_Pin;
  GPIO_InitStruct.Mode = GPIO_MODE_OUTPUT_PP;
  GPIO_InitStruct.Pull = GPIO_NOPULL;
  GPIO_InitStruct.Speed = GPIO_SPEED_FREQ_LOW;
  HAL_GPIO_Init(GPIOC, &GPIO_InitStruct);

  /*Configure GPIO pins : EXT_RST_Pin GYRO_INT1_Pin */
  GPIO_InitStruct.Pin = EXT_RST_Pin|GYRO_INT1_Pin;
  GPIO_InitStruct.Mode = GPIO_MODE_EVT_RISING;
  GPIO_InitStruct.Pull = GPIO_NOPULL;
  HAL_GPIO_Init(GPIOD, &GPIO_InitStruct);

  /*Configure GPIO pin : GYRO_CS_Pin */
  GPIO_InitStruct.Pin = GYRO_CS_Pin;
  GPIO_InitStruct.Mode = GPIO_MODE_OUTPUT_PP;
  GPIO_InitStruct.Pull = GPIO_NOPULL;
  GPIO_InitStruct.Speed = GPIO_SPEED_FREQ_VERY_HIGH;
  HAL_GPIO_Init(GYRO_CS_GPIO_Port, &GPIO_InitStruct);

  /*Configure GPIO pin : M3V3_REG_ON_Pin */
  GPIO_InitStruct.Pin = M3V3_REG_ON_Pin;
  GPIO_InitStruct.Mode = GPIO_MODE_OUTPUT_PP;
  GPIO_InitStruct.Pull = GPIO_NOPULL;
  GPIO_InitStruct.Speed = GPIO_SPEED_FREQ_LOW;
  HAL_GPIO_Init(M3V3_REG_ON_GPIO_Port, &GPIO_InitStruct);

  /*Configure GPIO pin : GYRO_INT2_Pin */
  GPIO_InitStruct.Pin = GYRO_INT2_Pin;
  GPIO_InitStruct.Mode = GPIO_MODE_EVT_RISING;
  GPIO_InitStruct.Pull = GPIO_NOPULL;
  HAL_GPIO_Init(GYRO_INT2_GPIO_Port, &GPIO_InitStruct);

  /*Configure GPIO pin : XL_CS_Pin */
  GPIO_InitStruct.Pin = XL_CS_Pin;
  GPIO_InitStruct.Mode = GPIO_MODE_OUTPUT_PP;
  GPIO_InitStruct.Pull = GPIO_NOPULL;
  GPIO_InitStruct.Speed = GPIO_SPEED_FREQ_LOW;
  HAL_GPIO_Init(XL_CS_GPIO_Port, &GPIO_InitStruct);

  /*Configure GPIO pin : XL_INT_Pin */
  GPIO_InitStruct.Pin = XL_INT_Pin;
  GPIO_InitStruct.Mode = GPIO_MODE_EVT_RISING;
  GPIO_InitStruct.Pull = GPIO_NOPULL;
  HAL_GPIO_Init(XL_INT_GPIO_Port, &GPIO_InitStruct);

}

void Error_Handler(void)
{
  __disable_irq();
  while (1)
  {
  }
}
